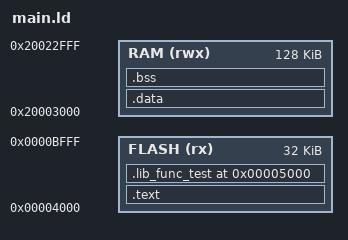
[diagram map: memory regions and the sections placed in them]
OUTPUT_FORMAT ("elf32-littlearm", "elf32-bigarm", "elf32-littlearm")

SEARCH_DIR(.)
GROUP(-lgcc -lc -lnosys)

MEMORY
{
  FLASH (rx) : ORIGIN = 0x04000, LENGTH = 0x08000
  RAM (rwx) :  ORIGIN = 0x20003000, LENGTH = 0x20000
}

SECTIONS
{
    .text :
    {
        KEEP(*(.init))
        KEEP(*(.fini))
        /* .ctors */
        *crtbegin.o(.ctors)
        *crtbegin?.o(.ctors)
        *(EXCLUDE_FILE(*crtend?.o *crtend.o) .ctors)
        *(SORT(.ctors.*))
        *(.ctors)

        /* .dtors */
        *crtbegin.o(.dtors)
        *crtbegin?.o(.dtors)
        *(EXCLUDE_FILE(*crtend?.o *crtend.o) .dtors)
        *(SORT(.dtors.*))
        *(.dtors)

        *(.rodata*)

        KEEP(*(.eh_frame*))
    } > FLASH

    .lib_func_test 0x5000:
    {
        . = ALIGN(16);
        KEEP(*(lib_func_test))
    } > FLASH

    . = ALIGN(4);
    __etext = 0x5100;

    .data : AT (__etext)
    {
        __data_start__ = .;
        *(vtable)
        *(.data*)

        . = ALIGN(4);
        /* preinit data */
        PROVIDE_HIDDEN (__preinit_array_start = .);
        KEEP(*(.preinit_array))
        PROVIDE_HIDDEN (__preinit_array_end = .);

        . = ALIGN(4);
        /* init data */
        PROVIDE_HIDDEN (__init_array_start = .);
        KEEP(*(SORT(.init_array.*)))
        KEEP(*(.init_array))
        PROVIDE_HIDDEN (__init_array_end = .);


        . = ALIGN(4);
        /* finit data */
        PROVIDE_HIDDEN (__fini_array_start = .);
        KEEP(*(SORT(.fini_array.*)))
        KEEP(*(.fini_array))
        PROVIDE_HIDDEN (__fini_array_end = .);

        KEEP(*(.jcr*))
        . = ALIGN(4);
        /* All data end */
        __data_end__ = .;

    } > RAM

    .bss :
    {
        . = ALIGN(4);
        __bss_start__ = .;
        *(.bss*)
        *(COMMON)
        . = ALIGN(4);
        __bss_end__ = .;
    } > RAM
}

